# QEMU_MPS2_AN385 register map
File version: 1.0
The CMSDK UART 0 of QEMU's mps2-an385 machine that the e2e program uses.
Registers are 32-bit, read-write, no defined reset value unless marked. A register's access mark holds for its fields unless they carry their own. Offsets are from the block's base; lines under a group give offsets from that group; [hi:lo] are bit positions; {n}, {i} and the like mark numbered series; 'fields as' and 'values as' point back to an identical list; <NAME> marks a mode.

## Memory map
0x40004000 UART0 — The CMSDK APB UART 0: the console of the machine.

## Interrupts
0 UART0_RX (UART0) — UART 0, receive.
1 UART0_TX (UART0) — UART 0, transmit.

## UART0 — The CMSDK APB UART 0: the console of the machine.
Base 0x40004000
0x00 DATA — Data: writing it sends a byte, reading it takes the byte received.
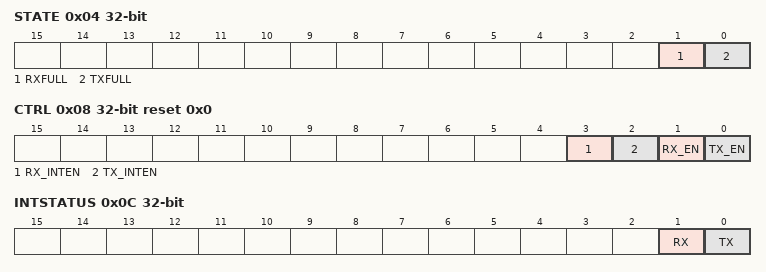
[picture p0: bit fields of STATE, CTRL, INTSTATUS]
0x04 STATE ro — State of the buffers.
  [1] RXFULL — The receive buffer is full.
  [0] TXFULL — The transmit buffer is full.
0x08 CTRL reset 0x0 — Control: the transmitter, the receiver and their interrupts.
  [3] RX_INTEN — A byte received raises the receive interrupt.
  [2] TX_INTEN — A byte sent raises the transmit interrupt.
  [1] RX_EN — The receiver is enabled.
  [0] TX_EN — The transmitter is enabled.
0x0C INTSTATUS — Interrupt status: writing a 1 to a bit clears it.
  [1] RX write-1-clears — The receive interrupt is raised.
  [0] TX write-1-clears — The transmit interrupt is raised.
0x10 BAUDDIV — Baud rate divisor: QEMU accepts 16 and more, and wants it set before the transmitter is enabled.
